# ESP32-S31 register map
Vendor: ESPRESSIF SYSTEMS (SHANGHAI) CO., LTD.; Series: ESP32 S-Series; File version: 1
CPU: RV32IMAFC r0p0, little endian, no MPU, FPU, 0 interrupt priority bits
Address unit: 32 bits
Registers are 32-bit, read-write, reset 0x0 unless marked. A register's access mark holds for its fields unless they carry their own. Offsets are from the block's base; [hi:lo] are bit positions; {n}, {i} and the like mark numbered series.

## HP_APM — HP_APM Peripheral
Base 0x20504400
0x00 REGION_FILTER_EN reset 0x1 — Region filter enable register
  [15:0] REGION_FILTER_EN — Configure bit 0 (0-15) to enable region 0.\\ 0: disable \\ 1: enable \\
{0x4+0xC*i} REGION{i}_ADDR_START (i=0..15) — Region address register
  [31:0] REGION_ADDR_START — Configures start address of region %s.
{0x8+0xC*i} REGION{i}_ADDR_END (i=0..15) reset 0xFFFFFFFF — Region address register
  [31:0] REGION_ADDR_END — Configures end address of region %s.
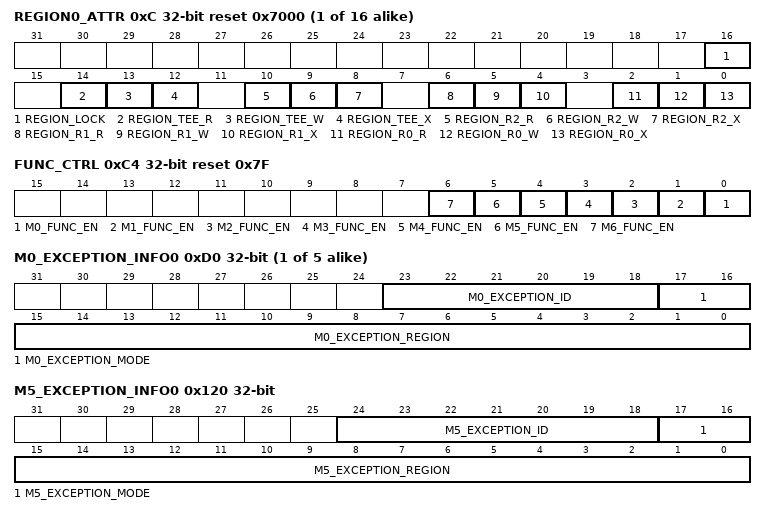
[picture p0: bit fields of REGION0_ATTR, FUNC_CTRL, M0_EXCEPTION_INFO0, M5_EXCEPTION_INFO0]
{0xC+0xC*i} REGION{i}_ATTR (i=0..15) reset 0x7000 — Region access authority attribute register
  [16] REGION_LOCK — Set 1 to lock region0 configuration
  [14] REGION_TEE_R — Configures the read authority of TEE_MODE in region %s.
  [13] REGION_TEE_W — Configures the write authority of TEE_MODE in region %s.
  [12] REGION_TEE_X — Configures the execution authority of TEE_MODE in region %s.
  [10] REGION_R2_R — Configures the read authority of REE_MODE 2 in region %s.
  [9] REGION_R2_W — Configures the write authority of REE_MODE 2 in region %s.
  [8] REGION_R2_X — Configures the execution authority of REE_MODE 2 in region %s.
  [6] REGION_R1_R — Configures the read authority of REE_MODE 1 in region %s.
  [5] REGION_R1_W — Configures the write authority of REE_MODE 1 in region %s.
  [4] REGION_R1_X — Configures the execution authority of REE_MODE 1 in region %s.
  [2] REGION_R0_R — Configures the read authority of REE_MODE 0 in region %s.
  [1] REGION_R0_W — Configures the write authority of REE_MODE 0 in region %s.
  [0] REGION_R0_X — Configures the execution authority of REE_MODE 0 in region %s.
0xC4 FUNC_CTRL reset 0x7F — APM function control register
  [n] M{n}_FUNC_EN (n=0..6) — PMS M{n} function enable
{0xC8+0x10*i} M{i}_STATUS ro (i=0..5)
  [1:0] M{i}_EXCEPTION_STATUS — Represents exception status.\\ bit0: 1 represents authority_exception \\ bit1: 1 represents space_exception \\
{0xCC+0x10*i} M{i}_STATUS_CLR wo (i=0..5) — M{i} status clear register
  [0] M{i}_EXCEPTION_STATUS_CLR — Configures to clear exception status.
{0xD0+0x10*i} M{i}_EXCEPTION_INFO0 ro (i=0..4)
  [23:18] M{i}_EXCEPTION_ID — Represents exception id information.
  [17:16] M{i}_EXCEPTION_MODE — Represents exception mode.
  [15:0] M{i}_EXCEPTION_REGION — Represents exception region.
{0xD4+0x10*i} M{i}_EXCEPTION_INFO1 ro (i=0..5)
  [31:0] M{i}_EXCEPTION_ADDR — Represents exception addr.
0x120 M5_EXCEPTION_INFO0 ro
  [24:18] M5_EXCEPTION_ID — Represents exception id information.
  [17:16] M5_EXCEPTION_MODE — Represents exception mode.
  [15:0] M5_EXCEPTION_REGION — Represents exception region.
0x12C M6_STATUS ro
  [1:0] M6_EXCEPTION_STATUS — Represents exception status.\\ bit0: 1 represents authority_exception \\ bit1: 1 represents space_exception \\
0x130 M6_STATUS_CLR wo — M6 status clear register
  [0] M6_EXCEPTION_STATUS_CLR — Configures to clear exception status.
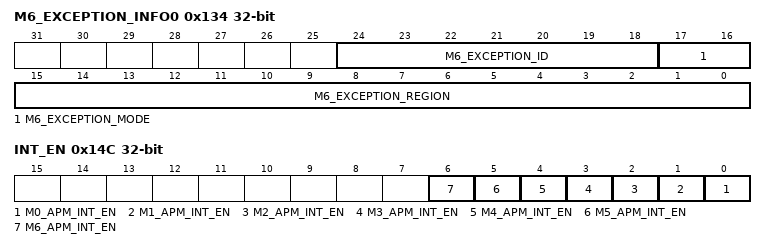
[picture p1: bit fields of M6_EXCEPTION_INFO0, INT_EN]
0x134 M6_EXCEPTION_INFO0 ro
  [24:18] M6_EXCEPTION_ID — Represents exception id information.
  [17:16] M6_EXCEPTION_MODE — Represents exception mode.
  [15:0] M6_EXCEPTION_REGION — Represents exception region.
0x138 M6_EXCEPTION_INFO1 ro
  [31:0] M6_EXCEPTION_ADDR — Represents exception addr.
0x14C INT_EN — APM interrupt enable register
  [n] M{n}_APM_INT_EN (n=0..6) — Configures to enable APM M{n} interrupt.\\ 0: disable \\ 1: enable \\
0x150 AXI_BLOCK_EN reset 0x1 — M6 status clear register
  [0] AXI_BLOCK_EN — Configures to if block transmission when get exceltion.\\ 0: transparent transmission to slave \\ 1: don't transparent transmission to slave \\
0x154 BUS_ERR_CONF — APM interrupt enable register
  [0] BUS_ERR_RESP_EN — Configures whether return error response to cpu when access blocked 0: disable error response \\ 1: enable error response \\
0x3F8 CLOCK_GATE reset 0x1 — Clock gating register
  [0] CLK_EN — Configures whether to keep the clock always on.\\ 0: enable automatic clock gating \\ 1: keep the clock always on \\
0x3FC DATE reset 0x2506260 — Version control register
  [27:0] DATE — Version control register.
